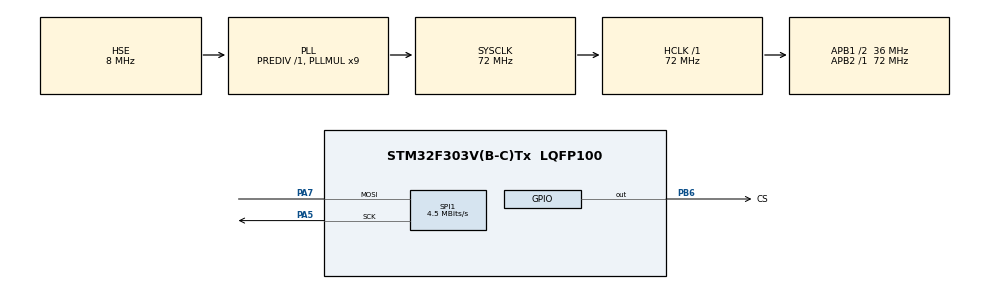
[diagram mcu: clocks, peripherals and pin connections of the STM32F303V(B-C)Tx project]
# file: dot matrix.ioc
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Mcu.Family=STM32F3
Mcu.Name=STM32F303V(B-C)Tx
Mcu.Package=LQFP100
NVIC.PriorityGroup=NVIC_PRIORITYGROUP_4
PA5.Mode=Simplex_Bidirectional_Master
PA5.Signal=SPI1_SCK
PA7.Mode=Simplex_Bidirectional_Master
PA7.Signal=SPI1_MOSI
PB6.GPIO_Label=CS
PB6.Signal=GPIO_Output
PF0-OSC_IN.Mode=HSE-External-Oscillator
PF0-OSC_IN.Signal=RCC_OSC_IN
PF1-OSC_OUT.Mode=HSE-External-Oscillator
PF1-OSC_OUT.Signal=RCC_OSC_OUT
ProjectManager.HeapSize=0x200
ProjectManager.StackSize=0x400
ProjectManager.TargetToolchain=STM32CubeIDE
RCC.AHBFreq_Value=72000000
RCC.APB1CLKDivider=RCC_HCLK_DIV2
RCC.APB1Freq_Value=36000000
RCC.APB1TimFreq_Value=72000000
RCC.APB2Freq_Value=72000000
RCC.APB2TimFreq_Value=72000000
RCC.CortexFreq_Value=72000000
RCC.HCLKFreq_Value=72000000
RCC.HSE_VALUE=8000000
RCC.HSI_VALUE=8000000
RCC.LSE_VALUE=32768
RCC.PLLMUL=RCC_PLL_MUL9
RCC.PLLSourceVirtual=RCC_PLLSOURCE_HSE
RCC.SYSCLKFreq_VALUE=72000000
RCC.SYSCLKSourceVirtual=RCC_SYSCLKSOURCE_PLLCLK
RCC.USBFreq_Value=72000000
SPI1.BaudRatePrescaler=SPI_BAUDRATEPRESCALER_16
SPI1.CalculateBaudRate=4.5 MBits/s
SPI1.Direction=SPI_DIRECTION_1LINE
SPI1.Mode=SPI_MODE_MASTER
SPI1.VirtualType=VM_MASTER
board=custom

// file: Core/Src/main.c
/* USER CODE BEGIN Header */
/**
  ******************************************************************************
  * @file           : main.c
  * @brief          : Main program body
  ******************************************************************************
  * @attention
  *
  * Copyright (c) 2024 STMicroelectronics.
  * All rights reserved.
  *
  * This software is licensed under terms that can be found in the LICENSE file
  * in the root directory of this software component.
  * If no LICENSE file comes with this software, it is provided AS-IS.
  *
  ******************************************************************************
  */
/* USER CODE END Header */
#include "main.h"

/* USER CODE BEGIN Includes */
#include "MAX7219.h"
/* USER CODE END Includes */

SPI_HandleTypeDef hspi1;

void SystemClock_Config(void);
static void MX_GPIO_Init(void);
static void MX_SPI1_Init(void);

int main(void)
{
  /* USER CODE BEGIN 1 */
   int Ch_no=0;
  /* USER CODE END 1 */

  /* MCU Configuration--------------------------------------------------------*/

  /* Reset of all peripherals, Initializes the Flash interface and the Systick. */
  HAL_Init();

  /* Configure the system clock */
  SystemClock_Config();

  /* Initialize all configured peripherals */
  MX_GPIO_Init();
  MX_SPI1_Init();
  /* USER CODE BEGIN 2 */

  MAX72_Init();

  /* USER CODE END 2 */

  /* Infinite loop */
  while (1)
  {

    /* USER CODE BEGIN 3 */
	  for (Ch_no=0;Ch_no<=38;Ch_no++)
		  {
			  Print_Alphanum (Ch_no);
			  HAL_Delay(400);
		  }
  }
  /* USER CODE END 3 */
}

void SystemClock_Config(void)
{
  RCC_OscInitTypeDef RCC_OscInitStruct = {0};
  RCC_ClkInitTypeDef RCC_ClkInitStruct = {0};

  /** Initializes the RCC Oscillators according to the specified parameters
  * in the RCC_OscInitTypeDef structure.
  */
  RCC_OscInitStruct.OscillatorType = RCC_OSCILLATORTYPE_HSE;
  RCC_OscInitStruct.HSEState = RCC_HSE_ON;
  RCC_OscInitStruct.HSEPredivValue = RCC_HSE_PREDIV_DIV1;
  RCC_OscInitStruct.HSIState = RCC_HSI_ON;
  RCC_OscInitStruct.PLL.PLLState = RCC_PLL_ON;
  RCC_OscInitStruct.PLL.PLLSource = RCC_PLLSOURCE_HSE;
  RCC_OscInitStruct.PLL.PLLMUL = RCC_PLL_MUL9;
  if (HAL_RCC_OscConfig(&RCC_OscInitStruct) != HAL_OK)
  {
    Error_Handler();
  }

  /** Initializes the CPU, AHB and APB buses clocks
  */
  RCC_ClkInitStruct.ClockType = RCC_CLOCKTYPE_HCLK|RCC_CLOCKTYPE_SYSCLK
                              |RCC_CLOCKTYPE_PCLK1|RCC_CLOCKTYPE_PCLK2;
  RCC_ClkInitStruct.SYSCLKSource = RCC_SYSCLKSOURCE_PLLCLK;
  RCC_ClkInitStruct.AHBCLKDivider = RCC_SYSCLK_DIV1;
  RCC_ClkInitStruct.APB1CLKDivider = RCC_HCLK_DIV2;
  RCC_ClkInitStruct.APB2CLKDivider = RCC_HCLK_DIV1;

  if (HAL_RCC_ClockConfig(&RCC_ClkInitStruct, FLASH_LATENCY_2) != HAL_OK)
  {
    Error_Handler();
  }
}

static void MX_SPI1_Init(void)
{

  /* SPI1 parameter configuration*/
  hspi1.Instance = SPI1;
  hspi1.Init.Mode = SPI_MODE_MASTER;
  hspi1.Init.Direction = SPI_DIRECTION_1LINE;
  hspi1.Init.DataSize = SPI_DATASIZE_4BIT;
  hspi1.Init.CLKPolarity = SPI_POLARITY_LOW;
  hspi1.Init.CLKPhase = SPI_PHASE_1EDGE;
  hspi1.Init.NSS = SPI_NSS_SOFT;
  hspi1.Init.BaudRatePrescaler = SPI_BAUDRATEPRESCALER_16;
  hspi1.Init.FirstBit = SPI_FIRSTBIT_MSB;
  hspi1.Init.TIMode = SPI_TIMODE_DISABLE;
  hspi1.Init.CRCCalculation = SPI_CRCCALCULATION_DISABLE;
  hspi1.Init.CRCPolynomial = 7;
  hspi1.Init.CRCLength = SPI_CRC_LENGTH_DATASIZE;
  hspi1.Init.NSSPMode = SPI_NSS_PULSE_ENABLE;
  if (HAL_SPI_Init(&hspi1) != HAL_OK)
  {
    Error_Handler();
  }

}

static void MX_GPIO_Init(void)
{
  GPIO_InitTypeDef GPIO_InitStruct = {0};

  /* GPIO Ports Clock Enable */
  __HAL_RCC_GPIOF_CLK_ENABLE();
  __HAL_RCC_GPIOA_CLK_ENABLE();
  __HAL_RCC_GPIOB_CLK_ENABLE();

  /*Configure GPIO pin Output Level */
  HAL_GPIO_WritePin(CS_GPIO_Port, CS_Pin, GPIO_PIN_RESET);

  /*Configure GPIO pin : CS_Pin */
  GPIO_InitStruct.Pin = CS_Pin;
  GPIO_InitStruct.Mode = GPIO_MODE_OUTPUT_PP;
  GPIO_InitStruct.Pull = GPIO_NOPULL;
  GPIO_InitStruct.Speed = GPIO_SPEED_FREQ_LOW;
  HAL_GPIO_Init(CS_GPIO_Port, &GPIO_InitStruct);

}

void Error_Handler(void)
{
  __disable_irq();
  while (1)
  {
  }
}
